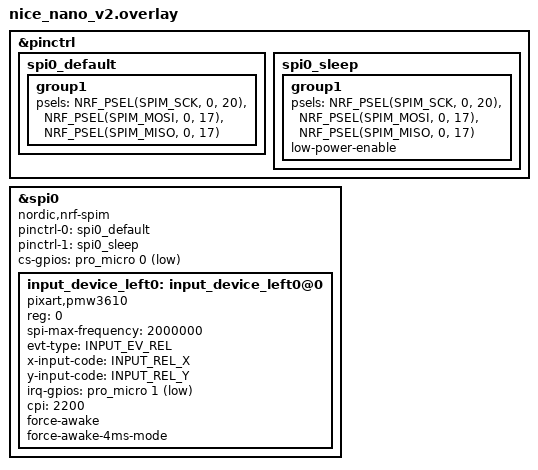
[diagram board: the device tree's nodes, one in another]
/**
 * Generated by Shield Wizard for ZMK
 * Applies to part "left" with controller "nice_nano_v2"
 */

// pin control for spi0
// - SCK on D3
// - MOSI on D2
// - MISO on D2
&pinctrl {
    /* configuration for spi0 device, default state */
    spi0_default: spi0_default {
        group1 {
            psels = <NRF_PSEL(SPIM_SCK, 0, 20)>,
                    <NRF_PSEL(SPIM_MOSI, 0, 17)>,
                    <NRF_PSEL(SPIM_MISO, 0, 17)>;
        };
    };
    /* configuration for spi0 device, sleep state */
    spi0_sleep: spi0_sleep {
        group1 {
            psels = <NRF_PSEL(SPIM_SCK, 0, 20)>,
                    <NRF_PSEL(SPIM_MOSI, 0, 17)>,
                    <NRF_PSEL(SPIM_MISO, 0, 17)>;
            low-power-enable;
        };
    };
};
&spi0 {
    compatible = "nordic,nrf-spim";
    status = "okay";
    pinctrl-0 = <&spi0_default>;
    pinctrl-1 = <&spi0_sleep>;
    pinctrl-names = "default", "sleep";

    // Leave at Zephyr's 0xff default. ORC is clocked out for 7 of the 8 bytes
    // of every motion burst read, and MOSI/MISO share P0.17, so those bytes go
    // onto the wire the sensor is driving. 0x00 was tried because in this
    // part's protocol the address MSB is the write bit, making 0xff decode as
    // "write register 0x7f" - the page select for the bank holding RES_STEP.
    // It made reads garbage: driving the shared line low fights the sensor's
    // data, so deltas came back huge and the cursor went random. 0xff is what
    // lets the sensor win the line. Do not set this to 0x00.
    // overrun-character = <0x00>;
};

// devices on spi0

// CS pins for devices on spi0
&spi0 {
    cs-gpios = <&pro_micro 0 GPIO_ACTIVE_LOW>;
};

#include <zephyr/dt-bindings/input/input-event-codes.h>

&spi0 {
    input_device_left0: input_device_left0@0 {
        status = "okay";
        compatible = "pixart,pmw3610";
        reg = <0>;
        // MOSI and MISO share P0.17 (3-wire SDIO), so the nRF drives the line
        // during every read's data phase while the sensor drives it too. 1MHz
        // was tried to buy timing margin on that contention and did NOT stop
        // the runtime RES_STEP corruption, so it is back at 2MHz rather than
        // paying double bus occupancy for nothing. See src/pmw3610_cpi_reassert.c.
        spi-max-frequency = <2000000>;
        evt-type = <INPUT_EV_REL>;
        x-input-code = <INPUT_REL_X>;
        y-input-code = <INPUT_REL_Y>;
        irq-gpios = <&pro_micro 1 (GPIO_ACTIVE_LOW | GPIO_PULL_UP)>;

        // Range 200-3200, step 200; a non-multiple is silently truncated, and
        // out of range aborts init. Kept above the sensitivity wanted so the
        // keymap can trim Y - scaling down avoids the quantization wobble that
        // scaling up produces on slow movement. Raising it also lowers the speed
        // at which the sensor's 12-bit delta registers wrap (see REST3 in
        // cosmos_keyboard_left.conf), so it is not a free knob.
        // Sets both axes: the keymap no longer scales either one, so this is the
        // only speed knob. Step 200 to retune.
        // Do not cut this to compensate for REPORT_INTERVAL_MIN=8: that gate
        // passed on nearly every sample anyway, so the loss it caused was
        // occasional, not proportional. 1400 was tried on that bad assumption
        // and made slow movement quantize to +-1 counts per sample, which the
        // host's pointer acceleration then damps into mush. That is the floor.
        // 2000 was tried for feel and reverted - 2200 is the settled value.
        cpi = <2200>;

        // Both of these together, never force-awake alone.
        //
        // Without force-awake the sensor downshifts to a REST mode, which gates
        // its SPI clock. Motion still fires the IRQ, but pmw3610_read() - unlike
        // pmw3610_write() - never issues SPI_CLK_ON_REQ, so the burst reads back
        // the bus overrun character instead. An all-0xff burst decodes to exactly
        // x=-1 y=-1, and the driver checks neither the MOTION bit nor anything
        // else, so it reports that as real motion: ~20 samples of -1/-1 drift at
        // the start of every swipe after a pause.
        //
        // force-awake keeps it in RUN while ZMK is ACTIVE so the clock is never
        // gated. Alone it is unsafe - the activity-state handler would
        // read-modify-write PERFORMANCE (0x11) through that same unclocked read
        // and write the garbage back. force-awake-4ms-mode makes that path write
        // a constant 0x0d instead, so the bad read never reaches the write.
        //
        // Costs battery: the sensor stays in RUN at a 4ms sample rate whenever
        // ZMK is active. The downshift table in cosmos_keyboard_left.conf now
        // only applies once ZMK reaches IDLE/SLEEP.
        force-awake;
        force-awake-4ms-mode;

        // Leave these off - orientation is done in the keymap by
        // &zip_xy_transform. The driver packs swap/invert into the same
        // unverified RES_STEP write as the CPI, so a failed write loses both.
        // invert-x;
        // invert-y;
        // swap-xy;
    };
};
